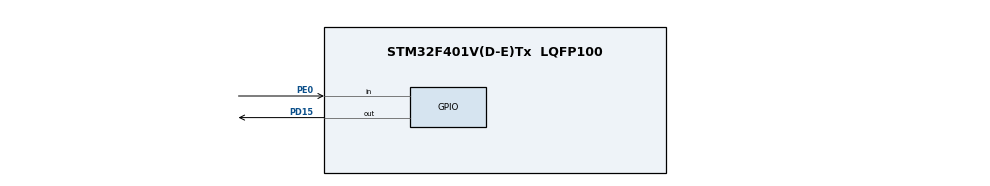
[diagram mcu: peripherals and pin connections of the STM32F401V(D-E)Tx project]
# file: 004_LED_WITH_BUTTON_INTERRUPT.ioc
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Mcu.Family=STM32F4
Mcu.Name=STM32F401V(D-E)Tx
Mcu.Package=LQFP100
NVIC.PriorityGroup=NVIC_PRIORITYGROUP_4
PD15.PinState=GPIO_PIN_RESET
PD15.Signal=GPIO_Output
PE0.GPIO_PuPd=GPIO_PULLDOWN
PE0.Signal=GPIO_Input
ProjectManager.HeapSize=0x200
ProjectManager.StackSize=0x400
ProjectManager.TargetToolchain=STM32CubeIDE
board=custom

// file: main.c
/* USER CODE BEGIN Header */
/**
 ******************************************************************************
 * @file           : main.c
 * @brief          : Main program body
 ******************************************************************************
 * @attention
 *
 * Copyright (c) 2023 STMicroelectronics.
 * All rights reserved.
 *
 * This software is licensed under terms that can be found in the LICENSE file
 * in the root directory of this software component.
 * If no LICENSE file comes with this software, it is provided AS-IS.
 *
 ******************************************************************************
 */
/* USER CODE END Header */
#include "main.h"

void SystemClock_Config(void);
static void MX_GPIO_Init(void);

int main(void)
{

  /* MCU Configuration--------------------------------------------------------*/

  /* Reset of all peripherals, Initializes the Flash interface and the Systick. */
  HAL_Init();

  /* Configure the system clock */
  SystemClock_Config();

  /* Initialize all configured peripherals */
  MX_GPIO_Init();

  /* Infinite loop */
	while (1) {

	}
}

void SystemClock_Config(void)
{
  RCC_OscInitTypeDef RCC_OscInitStruct = {0};
  RCC_ClkInitTypeDef RCC_ClkInitStruct = {0};

  /** Configure the main internal regulator output voltage
  */
  __HAL_RCC_PWR_CLK_ENABLE();
  __HAL_PWR_VOLTAGESCALING_CONFIG(PWR_REGULATOR_VOLTAGE_SCALE2);

  /** Initializes the RCC Oscillators according to the specified parameters
  * in the RCC_OscInitTypeDef structure.
  */
  RCC_OscInitStruct.OscillatorType = RCC_OSCILLATORTYPE_HSI;
  RCC_OscInitStruct.HSIState = RCC_HSI_ON;
  RCC_OscInitStruct.HSICalibrationValue = RCC_HSICALIBRATION_DEFAULT;
  RCC_OscInitStruct.PLL.PLLState = RCC_PLL_NONE;
  if (HAL_RCC_OscConfig(&RCC_OscInitStruct) != HAL_OK)
  {
    Error_Handler();
  }

  /** Initializes the CPU, AHB and APB buses clocks
  */
  RCC_ClkInitStruct.ClockType = RCC_CLOCKTYPE_HCLK|RCC_CLOCKTYPE_SYSCLK
                              |RCC_CLOCKTYPE_PCLK1|RCC_CLOCKTYPE_PCLK2;
  RCC_ClkInitStruct.SYSCLKSource = RCC_SYSCLKSOURCE_HSI;
  RCC_ClkInitStruct.AHBCLKDivider = RCC_SYSCLK_DIV1;
  RCC_ClkInitStruct.APB1CLKDivider = RCC_HCLK_DIV1;
  RCC_ClkInitStruct.APB2CLKDivider = RCC_HCLK_DIV1;

  if (HAL_RCC_ClockConfig(&RCC_ClkInitStruct, FLASH_LATENCY_0) != HAL_OK)
  {
    Error_Handler();
  }
}

static void MX_GPIO_Init(void)
{
  GPIO_InitTypeDef GPIO_InitStruct = {0};

  /* GPIO Ports Clock Enable */
  __HAL_RCC_GPIOD_CLK_ENABLE();
  __HAL_RCC_GPIOE_CLK_ENABLE();

  /*Configure GPIO pin Output Level */
  HAL_GPIO_WritePin(GPIOD, GPIO_PIN_15, GPIO_PIN_RESET);

  /*Configure GPIO pin : PD15 */
  GPIO_InitStruct.Pin = GPIO_PIN_15;
  GPIO_InitStruct.Mode = GPIO_MODE_OUTPUT_PP;
  GPIO_InitStruct.Pull = GPIO_NOPULL;
  GPIO_InitStruct.Speed = GPIO_SPEED_FREQ_LOW;
  HAL_GPIO_Init(GPIOD, &GPIO_InitStruct);

  /*Configure GPIO pin : PE0 */
  GPIO_InitStruct.Pin = GPIO_PIN_0;
  GPIO_InitStruct.Mode = GPIO_MODE_INPUT;
  GPIO_InitStruct.Pull = GPIO_PULLDOWN;
  HAL_GPIO_Init(GPIOE, &GPIO_InitStruct);

/* USER CODE BEGIN MX_GPIO_Init_2 */
	__HAL_RCC_SYSCFG_CLK_ENABLE();

	NVIC_SetPriority(EXTI0_IRQn, 1);
	NVIC_EnableIRQ(EXTI0_IRQn);

	SYSCFG->EXTICR[0] |= SYSCFG_EXTICR1_EXTI0_PE;

	EXTI->IMR |= EXTI_IMR_IM0;
	EXTI->FTSR |= EXTI_FTSR_TR0;

/* USER CODE END MX_GPIO_Init_2 */
}

/* USER CODE BEGIN 4 */
void EXTI0_IRQHandler(void) {
	if ((EXTI->PR & EXTI_PR_PR0) == EXTI_PR_PR0) {
		HAL_GPIO_TogglePin(GPIOD, GPIO_PIN_15);
	}
}

/* USER CODE END 4 */

void Error_Handler(void)
{
	__disable_irq();
	while (1) {
	}
}
